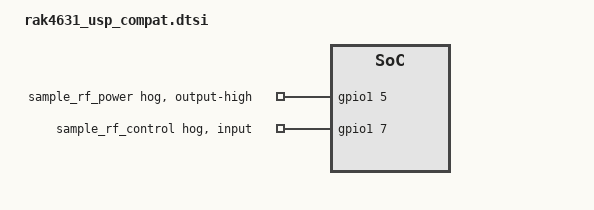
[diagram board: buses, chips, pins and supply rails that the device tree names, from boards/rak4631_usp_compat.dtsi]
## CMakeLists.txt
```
# SPDX-License-Identifier: Apache-2.0

cmake_minimum_required(VERSION 3.20.0)

find_package(Zephyr REQUIRED HINTS $ENV{ZEPHYR_BASE})
project(rzi_lorawan_class_a)

target_sources(app PRIVATE src/main.c)
```

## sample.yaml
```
# SPDX-License-Identifier: Apache-2.0

sample:
  name: RZI LoRaWAN Class A
  description: >
    Join a LoRaWAN network and send periodic uplinks through the RZI C API
tests:
  sample.rzi.lorawan.class_a:
    sysbuild: true
    build_only: true
    tags:
      - rzi
      - lorawan
    platform_allow:
      - rzi_rak4631/nrf52840
      - rzi_rak3372/stm32wle5xx
    integration_platforms:
      - rzi_rak4631/nrf52840
      - rzi_rak3372/stm32wle5xx
```

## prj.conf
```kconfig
# SPDX-License-Identifier: Apache-2.0

CONFIG_GPIO=y
CONFIG_SPI=y
CONFIG_FLASH=y
CONFIG_PM_DEVICE=y
CONFIG_TEST_RANDOM_GENERATOR=y

CONFIG_LOG=y
CONFIG_SERIAL=y
CONFIG_CONSOLE=y
CONFIG_UART_CONSOLE=y
CONFIG_UART_LINE_CTRL=y
CONFIG_USB_DEVICE_STACK_NEXT=y
CONFIG_CDC_ACM_SERIAL_INITIALIZE_AT_BOOT=y
CONFIG_LOG_PROCESS_THREAD_STARTUP_DELAY_MS=4000
CONFIG_USBD_CDC_ACM_LOG_LEVEL_OFF=y
CONFIG_USBD_LOG_LEVEL_OFF=y
CONFIG_MAIN_STACK_SIZE=4096
CONFIG_HEAP_MEM_POOL_SIZE=8192

CONFIG_LORA=n
CONFIG_LORAWAN=n

CONFIG_RZI=y
CONFIG_RZI_LORAWAN=y
CONFIG_RZI_POWER=y
CONFIG_RZI_MCUBOOT=y
CONFIG_STREAM_FLASH=y
CONFIG_IMG_MANAGER=y
CONFIG_LORA_BASICS_MODEM_DRIVERS_EVENT_TRIGGER_NO_THREAD=y
```

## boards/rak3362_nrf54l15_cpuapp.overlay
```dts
/* SPDX-License-Identifier: Apache-2.0 */
/*
 * rak3362 describes the SX1262 with the legacy semtech,sx1262 binding.
 * USP enables CONFIG_SEMTECH_SX126X only for semtech,sx1262-new.
 * A board overlay replaces app.overlay, so pull that file in first.
 */

#include "../app.overlay"
#include <zephyr/dt-bindings/usp/sx126x.h>

&lora {
	compatible = "semtech,sx1262-new";
	/delete-property/ dio2-tx-enable;
	/delete-property/ dio3-tcxo-voltage;
	/delete-property/ tcxo-power-startup-delay-ms;

	dio2-as-rf-switch;
	dio3-as-tcxo-control;
	tcxo-voltage = <SX126X_TCXO_SUPPLY_1_8V>;
	tcxo-wakeup-time = <5>;
	reg-mode = <SX126X_REG_MODE_DCDC>;
};
```

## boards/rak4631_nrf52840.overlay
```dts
/* SPDX-License-Identifier: Apache-2.0 */
/*
 * Upstream Zephyr rak4631 describes the SX1262 with the legacy semtech,sx1262
 * binding and a 3.3 V TCXO. USP enables CONFIG_SEMTECH_SX126X only for
 * semtech,sx1262-new. The board already selects the USB CDC console.
 * A board overlay replaces app.overlay, so pull that file in first.
 */

#include "../app.overlay"
#include <zephyr/dt-bindings/usp/sx126x.h>

/ {
	chosen {
		zephyr,lorawan-transceiver = &lora;
	};
};

&lora {
	compatible = "semtech,sx1262-new";
	/delete-property/ dio2-tx-enable;
	/delete-property/ dio3-tcxo-voltage;
	/delete-property/ tcxo-power-startup-delay-ms;
	/delete-property/ rx-enable-gpios;

	dio2-as-rf-switch;
	dio3-as-tcxo-control;
	tcxo-voltage = <SX126X_TCXO_SUPPLY_3_3V>;
	tcxo-wakeup-time = <5>;
	reg-mode = <SX126X_REG_MODE_DCDC>;
};
```

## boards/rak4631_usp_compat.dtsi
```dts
/* SPDX-License-Identifier: Apache-2.0 */
/* Sample-only adapter for the pinned RAK4631 BSP and USP SX1262 driver. */
#include <zephyr/dt-bindings/usp/sx126x.h>

/ {
	chosen {
		zephyr,lorawan-transceiver = &lora;
	};
};

&lora {
	compatible = "semtech,sx1262-new";
	dio1-gpios = <&gpio1 15 (GPIO_ACTIVE_HIGH | GPIO_PULL_DOWN)>;
	dio2-as-rf-switch;
	dio3-as-tcxo-control;
	tcxo-voltage = <SX126X_TCXO_SUPPLY_3_3V>;
	tcxo-wakeup-time = <5>;
	reg-mode = <SX126X_REG_MODE_DCDC>;
	/delete-property/ dio2-tx-enable;
	/delete-property/ dio3-tcxo-voltage;
	/delete-property/ tcxo-power-startup-delay-ms;
	/delete-property/ rx-enable-gpios;
};

&gpio1 {
	sample_rf_power: sample-rf-power {
		gpio-hog;
		gpios = <5 GPIO_ACTIVE_HIGH>;
		output-high;
	};
	sample_rf_control: sample-rf-control {
		gpio-hog;
		gpios = <7 GPIO_ACTIVE_HIGH>;
		input;
	};
};
```

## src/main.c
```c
/* SPDX-License-Identifier: Apache-2.0 */

#include <errno.h>
#include <zephyr/devicetree.h>
#include <zephyr/kernel.h>
#include <zephyr/logging/log.h>
#include <rzi/lorawan/lorawan.h>
#include <rzi/power/power.h>

static __maybe_unused void ignore_result(int result)
{
	ARG_UNUSED(result);
}

LOG_MODULE_REGISTER(rzi_lorawan_sample, LOG_LEVEL_INF);

#define USER_NODE          DT_PATH(zephyr_user)
#define REGION_ENUM(name)  DT_CAT(RZI_LORAWAN_REGION_, name)
#define RETRY_DELAY_MS     5000
#define UPLINK_INTERVAL_MS 60000

static volatile bool stack_ready;
static volatile bool joined;
static volatile bool join_failed;

static int configure_credentials(void)
{
	static const uint8_t dev_eui[] = DT_PROP(USER_NODE, user_lorawan_device_eui);
	static const uint8_t join_eui[] = DT_PROP(USER_NODE, user_lorawan_join_eui);
	static const uint8_t app_key[] = DT_PROP(USER_NODE, user_lorawan_app_key);
	static const uint8_t gen_app_key[] = DT_PROP(USER_NODE, user_lorawan_gen_app_key);
	int rc = rzi_lorawan_set_dev_eui(dev_eui, sizeof(dev_eui));

	if (rc == 0) {
		rc = rzi_lorawan_set_app_eui(join_eui, sizeof(join_eui));
	}
	if (rc == 0) {
		rc = rzi_lorawan_set_app_key(app_key, sizeof(app_key));
	}
	if (rc == 0) {
		rc = rzi_lorawan_set_gen_app_key(gen_app_key, sizeof(gen_app_key));
	}
	if (rc == 0) {
		rc = rzi_lorawan_set_activation(RZI_LORAWAN_ACTIVATION_OTAA);
	}
	return rc;
}

static void wait_until(volatile bool *flag)
{
	while (!*flag) {
		k_sleep(K_MSEC(10));
	}
}

static void on_event(const struct rzi_lorawan_event *event, void *user_data)
{
	ARG_UNUSED(user_data);
	switch (event->type) {
	case RZI_LORAWAN_EVENT_READY:
		stack_ready = true;
		break;
	case RZI_LORAWAN_EVENT_STATE_CHANGED:
		if (event->state == RZI_LORAWAN_STATE_READY) {
			stack_ready = true;
		}
		break;
	case RZI_LORAWAN_EVENT_JOINED:
		joined = true;
		join_failed = false;
		break;
	case RZI_LORAWAN_EVENT_JOIN_FAILED:
		joined = false;
		join_failed = true;
		break;
	case RZI_LORAWAN_EVENT_TX_DONE:
		LOG_INF("Uplink complete: %d", event->tx.status);
		break;
	case RZI_LORAWAN_EVENT_DOWNLINK:
		LOG_INF("Downlink: port %u, %u bytes, RSSI %d dBm, SNR %d/4 dB",
			event->downlink.port, (unsigned int)event->downlink.size,
			event->downlink.rssi_dbm, event->downlink.snr_quarter_db);
		break;
	case RZI_LORAWAN_EVENT_ERROR:
		LOG_ERR("RZI error: %d", event->error);
		break;
	default:
		break;
	}
}

static const struct rzi_lorawan_callbacks callbacks = {
	.on_event = on_event,
};

static int request_join(void)
{
	int rc;

	joined = false;
	join_failed = false;
	rc = rzi_lorawan_join(1, 0, RZI_LORAWAN_JOIN_INTERVAL_DEFAULT, 0);
	if (rc != 0) {
		LOG_WRN("Join request rejected: %d", rc);
		return rc;
	}
	while (!joined && !join_failed) {
		k_sleep(K_MSEC(10));
	}
	return joined ? 0 : -RZI_ERR_NOT_READY;
}

int main(void)
{
	static const uint8_t payload[] = "Hello from RZI";
	rzi_lorawan_callback_handle_t handle;
	int rc;

	LOG_INF("RZI LoRaWAN Class A sample");
	rc = rzi_power_init();
	if (rc != 0) {
		LOG_ERR("Power init failed: %d", rc);
		return rc;
	}
	rc = rzi_lorawan_register_callbacks(&callbacks, &handle);
	if (rc != 0) {
		LOG_ERR("Callback registration failed: %d", rc);
		return rc;
	}
	rc = configure_credentials();
	if (rc == 0) {
		rc = rzi_lorawan_set_region(
			REGION_ENUM(DT_STRING_UNQUOTED(USER_NODE, user_lorawan_region)));
	}
	if (rc == 0) {
		rc = rzi_lorawan_start();
	}
	if (rc != 0) {
		LOG_ERR("Start failed: %d", rc);
		return rc;
	}

	wait_until(&stack_ready);

	while (request_join() != 0) {
		ignore_result(rzi_lorawan_leave());
		ignore_result(rzi_power_sleep(RETRY_DELAY_MS));
	}
	LOG_INF("Joined");

	for (;;) {
		rc = rzi_lorawan_send(1, payload, sizeof(payload) - 1, RZI_LORAWAN_MSG_UNCONFIRMED);
		if (rc != 0 && rc != -RZI_ERR_BUSY) {
			LOG_WRN("Uplink rejected: %d", rc);
		}
		ignore_result(rzi_power_sleep(UPLINK_INTERVAL_MS));
	}
}
```

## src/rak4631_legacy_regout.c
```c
/* SPDX-License-Identifier: Apache-2.0 */
/* Sample-only board compatibility for the currently pinned Zephyr BSP. */

#include <zephyr/init.h>
#include <hal/nrf_power.h>

void board_early_init_hook(void)
{
	if ((nrf_power_mainregstatus_get(NRF_POWER) == NRF_POWER_MAINREGSTATUS_HIGH) &&
	    ((NRF_UICR->REGOUT0 & UICR_REGOUT0_VOUT_Msk) ==
	     (UICR_REGOUT0_VOUT_DEFAULT << UICR_REGOUT0_VOUT_Pos))) {
		NRF_NVMC->CONFIG = NVMC_CONFIG_WEN_Wen << NVMC_CONFIG_WEN_Pos;
		while (NRF_NVMC->READY == NVMC_READY_READY_Busy) {
			;
		}

		NRF_UICR->REGOUT0 = (NRF_UICR->REGOUT0 & ~((uint32_t)UICR_REGOUT0_VOUT_Msk)) |
				    (UICR_REGOUT0_VOUT_3V3 << UICR_REGOUT0_VOUT_Pos);

		NRF_NVMC->CONFIG = NVMC_CONFIG_WEN_Ren << NVMC_CONFIG_WEN_Pos;
		while (NRF_NVMC->READY == NVMC_READY_READY_Busy) {
			;
		}

		NVIC_SystemReset();
	}
}
```
